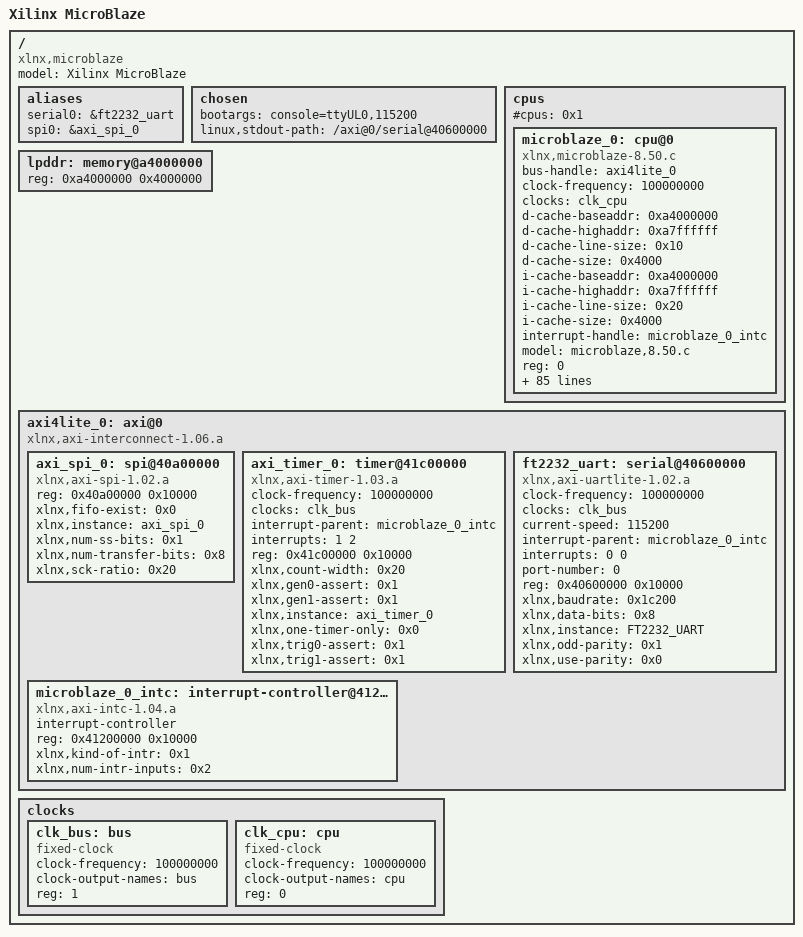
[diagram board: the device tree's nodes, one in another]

/dts-v1/;
/ {
	#address-cells = <1>;
	#size-cells = <1>;
	compatible = "xlnx,microblaze";
	model = "Xilinx MicroBlaze";
	aliases {
		serial0 = &ft2232_uart;
		spi0 = &axi_spi_0;
	} ;
	chosen {
		bootargs = "console=ttyUL0,115200";
		linux,stdout-path = "/axi@0/serial@40600000";
	} ;
	cpus {
		#address-cells = <1>;
		#cpus = <0x1>;
		#size-cells = <0>;
		microblaze_0: cpu@0 {
			bus-handle = <&axi4lite_0>;
			clock-frequency = <100000000>;
			clocks = <&clk_cpu>;
			compatible = "xlnx,microblaze-8.50.c";
			d-cache-baseaddr = <0xa4000000>;
			d-cache-highaddr = <0xa7ffffff>;
			d-cache-line-size = <0x10>;
			d-cache-size = <0x4000>;
			device_type = "cpu";
			i-cache-baseaddr = <0xa4000000>;
			i-cache-highaddr = <0xa7ffffff>;
			i-cache-line-size = <0x20>;
			i-cache-size = <0x4000>;
			interrupt-handle = <&microblaze_0_intc>;
			model = "microblaze,8.50.c";
			reg = <0>;
			timebase-frequency = <100000000>;
			xlnx,addr-tag-bits = <0xc>;
			xlnx,allow-dcache-wr = <0x1>;
			xlnx,allow-icache-wr = <0x1>;
			xlnx,area-optimized = <0x0>;
			xlnx,avoid-primitives = <0x0>;
			xlnx,base-vectors = <0x0>;
			xlnx,branch-target-cache-size = <0x0>;
			xlnx,cache-byte-size = <0x4000>;
			xlnx,d-axi = <0x1>;
			xlnx,d-lmb = <0x1>;
			xlnx,d-plb = <0x0>;
			xlnx,data-size = <0x20>;
			xlnx,dcache-addr-tag = <0xc>;
			xlnx,dcache-always-used = <0x1>;
			xlnx,dcache-byte-size = <0x4000>;
			xlnx,dcache-data-width = <0x0>;
			xlnx,dcache-force-tag-lutram = <0x0>;
			xlnx,dcache-interface = <0x0>;
			xlnx,dcache-line-len = <0x4>;
			xlnx,dcache-use-fsl = <0x0>;
			xlnx,dcache-use-writeback = <0x0>;
			xlnx,dcache-victims = <0x0>;
			xlnx,debug-enabled = <0x1>;
			xlnx,div-zero-exception = <0x1>;
			xlnx,dynamic-bus-sizing = <0x1>;
			xlnx,ecc-use-ce-exception = <0x0>;
			xlnx,edge-is-positive = <0x1>;
			xlnx,endianness = <0x1>;
			xlnx,fault-tolerant = <0x0>;
			xlnx,fpu-exception = <0x0>;
			xlnx,freq = <0x5f5e100>;
			xlnx,fsl-data-size = <0x20>;
			xlnx,fsl-exception = <0x0>;
			xlnx,fsl-links = <0x0>;
			xlnx,i-axi = <0x0>;
			xlnx,i-lmb = <0x1>;
			xlnx,i-plb = <0x0>;
			xlnx,icache-always-used = <0x1>;
			xlnx,icache-data-width = <0x0>;
			xlnx,icache-force-tag-lutram = <0x0>;
			xlnx,icache-interface = <0x0>;
			xlnx,icache-line-len = <0x8>;
			xlnx,icache-streams = <0x1>;
			xlnx,icache-use-fsl = <0x0>;
			xlnx,icache-victims = <0x8>;
			xlnx,ill-opcode-exception = <0x1>;
			xlnx,instance = "microblaze_0";
			xlnx,interconnect = <0x2>;
			xlnx,interrupt-is-edge = <0x0>;
			xlnx,lockstep-slave = <0x0>;
			xlnx,mmu-dtlb-size = <0x4>;
			xlnx,mmu-itlb-size = <0x2>;
			xlnx,mmu-privileged-instr = <0x0>;
			xlnx,mmu-tlb-access = <0x3>;
			xlnx,mmu-zones = <0x2>;
			xlnx,number-of-pc-brk = <0x1>;
			xlnx,number-of-rd-addr-brk = <0x0>;
			xlnx,number-of-wr-addr-brk = <0x0>;
			xlnx,opcode-0x0-illegal = <0x1>;
			xlnx,optimization = <0x0>;
			xlnx,pc-width = <0x20>;
			xlnx,pvr = <0x2>;
			xlnx,pvr-user1 = <0x0>;
			xlnx,pvr-user2 = <0x0>;
			xlnx,reset-msr = <0x0>;
			xlnx,sco = <0x0>;
			xlnx,stream-interconnect = <0x0>;
			xlnx,unaligned-exceptions = <0x1>;
			xlnx,use-barrel = <0x1>;
			xlnx,use-branch-target-cache = <0x0>;
			xlnx,use-dcache = <0x1>;
			xlnx,use-div = <0x1>;
			xlnx,use-ext-brk = <0x1>;
			xlnx,use-ext-nm-brk = <0x1>;
			xlnx,use-extended-fsl-instr = <0x0>;
			xlnx,use-fpu = <0x0>;
			xlnx,use-hw-mul = <0x2>;
			xlnx,use-icache = <0x1>;
			xlnx,use-interrupt = <0x1>;
			xlnx,use-mmu = <0x3>;
			xlnx,use-msr-instr = <0x1>;
			xlnx,use-pcmp-instr = <0x1>;
			xlnx,use-reorder-instr = <0x1>;
			xlnx,use-stack-protection = <0x0>;
		} ;
	} ;
	lpddr: memory@a4000000 {
		device_type = "memory";
		reg = <0xa4000000 0x4000000>;
	} ;
	axi4lite_0: axi@0 {
		#address-cells = <1>;
		#size-cells = <1>;
		compatible = "xlnx,axi-interconnect-1.06.a", "simple-bus";
		ranges ;
		axi_spi_0: spi@40a00000 {
			compatible = "xlnx,axi-spi-1.02.a", "xlnx,xps-spi-2.00.a";
			reg = <0x40a00000 0x10000>;
			xlnx,fifo-exist = <0x0>;
			xlnx,instance = "axi_spi_0";
			xlnx,num-ss-bits = <0x1>;
			xlnx,num-transfer-bits = <0x8>;
			xlnx,sck-ratio = <0x20>;
		} ;
		axi_timer_0: timer@41c00000 {
			clock-frequency = <100000000>;
			clocks = <&clk_bus>;
			compatible = "xlnx,axi-timer-1.03.a", "xlnx,xps-timer-1.00.a";
			interrupt-parent = <&microblaze_0_intc>;
			interrupts = <1 2>;
			reg = <0x41c00000 0x10000>;
			xlnx,count-width = <0x20>;
			xlnx,gen0-assert = <0x1>;
			xlnx,gen1-assert = <0x1>;
			xlnx,instance = "axi_timer_0";
			xlnx,one-timer-only = <0x0>;
			xlnx,trig0-assert = <0x1>;
			xlnx,trig1-assert = <0x1>;
		} ;
		ft2232_uart: serial@40600000 {
			clock-frequency = <100000000>;
			clocks = <&clk_bus>;
			compatible = "xlnx,axi-uartlite-1.02.a", "xlnx,xps-uartlite-1.00.a";
			current-speed = <115200>;
			device_type = "serial";
			interrupt-parent = <&microblaze_0_intc>;
			interrupts = <0 0>;
			port-number = <0>;
			reg = <0x40600000 0x10000>;
			xlnx,baudrate = <0x1c200>;
			xlnx,data-bits = <0x8>;
			xlnx,instance = "FT2232_UART";
			xlnx,odd-parity = <0x1>;
			xlnx,use-parity = <0x0>;
		} ;
		microblaze_0_intc: interrupt-controller@41200000 {
			#interrupt-cells = <0x2>;
			compatible = "xlnx,axi-intc-1.04.a", "xlnx,xps-intc-1.00.a";
			interrupt-controller ;
			reg = <0x41200000 0x10000>;
			xlnx,kind-of-intr = <0x1>;
			xlnx,num-intr-inputs = <0x2>;
		} ;
	} ;
	clocks {
		#address-cells = <1>;
		#size-cells = <0>;
		clk_bus: bus {
			#clock-cells = <0>;
			clock-frequency = <100000000>;
			clock-output-names = "bus";
			compatible = "fixed-clock";
			reg = <1>;
		} ;
		clk_cpu: cpu {
			#clock-cells = <0>;
			clock-frequency = <100000000>;
			clock-output-names = "cpu";
			compatible = "fixed-clock";
			reg = <0>;
		} ;
	} ;
} ;

